# AT32F437xx_v2 register map
Vendor: Keil; Series: AT32F437; File version: 1.0
CPU: CM4 r0p1, little endian, no MPU, FPU, 4 interrupt priority bits
Registers are 32-bit, read-write, reset 0x0 unless marked. A register's access mark holds for its fields unless they carry their own. Offsets are from the block's base; [hi:lo] are bit positions; {n}, {i} and the like mark numbered series.

## USB_OTG1_GLOBAL — USB on-the-go full speed
Base 0x50000000
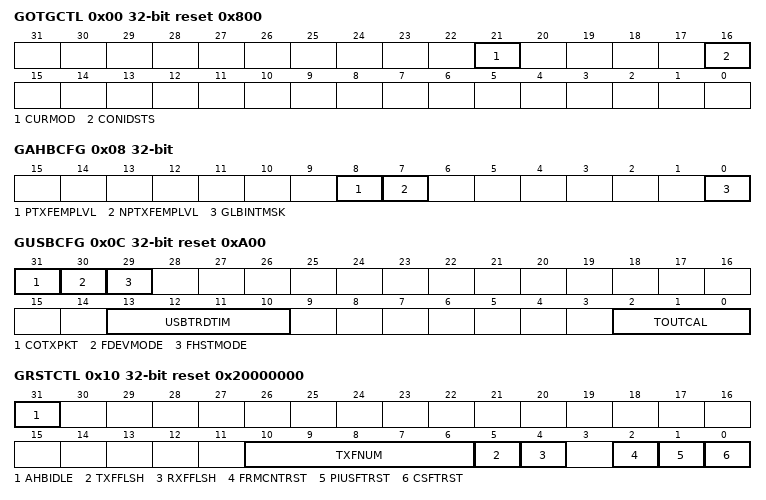
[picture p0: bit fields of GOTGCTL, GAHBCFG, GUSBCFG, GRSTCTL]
0x00 GOTGCTL reset 0x800 — OTGFS control and status register (OTGFS_GOTGCTL)
  [21] CURMOD ro — Current Mode of Operation
  [16] CONIDSTS ro — Connector ID status
0x04 GOTGINT — OTGFS interrupt register (OTGFS_GOTGINT)
  [2] SESENDDET — VBUS is deasserted
0x08 GAHBCFG — OTGFS AHB configuration register (OTGFS_GAHBCFG)
  [8] PTXFEMPLVL — Periodic TxFIFO empty level
  [7] NPTXFEMPLVL — Non-Periodic TxFIFO empty level
  [0] GLBINTMSK — Global interrupt mask
0x0C GUSBCFG reset 0xA00 — USB configuration register (OTGFS_GUSBCFG)
  [31] COTXPKT — Corrupt Tx packet
  [30] FDEVMODE — Force device mode
  [29] FHSTMODE — Force host mode
  [13:10] USBTRDTIM — USB turnaround time
  [2:0] TOUTCAL — FS timeout calibration
0x10 GRSTCTL reset 0x20000000 — OTGFS reset register (OTGFS_GRSTCTL)
  [31] AHBIDLE ro — AHB master idle
  [10:6] TXFNUM — TxFIFO number
  [5] TXFFLSH — TxFIFO flush
  [4] RXFFLSH — RxFIFO flush
  [2] FRMCNTRST — Host frame counter reset
  [1] PIUSFTRST — PIU FS Dedicated Controller Soft Reset
  [0] CSFTRST — Core soft reset
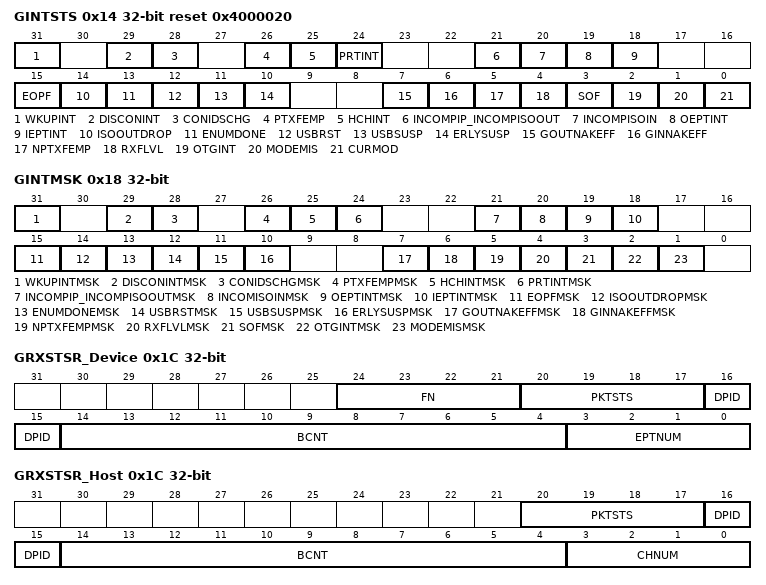
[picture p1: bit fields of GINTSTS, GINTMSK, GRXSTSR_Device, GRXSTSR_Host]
0x14 GINTSTS reset 0x4000020 — OTGFS core interrupt register (OTGFS_GINTSTS)
  [31] WKUPINT — Resume/remote wakeup detected interrupt
  [29] DISCONINT — Disconnect detected interrupt
  [28] CONIDSCHG — Connector ID status change
  [26] PTXFEMP ro — Periodic TxFIFO empty
  [25] HCHINT ro — Host channels interrupt
  [24] PRTINT ro — Host port interrupt
  [21] INCOMPIP_INCOMPISOOUT — Incomplete periodic transfer(Host mode)/Incomplete isochronous OUT transfer(Device mode)
  [20] INCOMPISOIN — Incomplete isochronous IN transfer
  [19] OEPTINT ro — OUT endpoint interrupt
  [18] IEPTINT ro — IN endpoint interrupt
  [15] EOPF — End of periodic frame interrupt
  [14] ISOOUTDROP — Isochronous OUT packet dropped interrupt
  [13] ENUMDONE — Enumeration done
  [12] USBRST — USB reset
  [11] USBSUSP — USB suspend
  [10] ERLYSUSP — Early suspend
  [7] GOUTNAKEFF ro — Global OUT NAK effective
  [6] GINNAKEFF ro — Global IN non-periodic NAK effective
  [5] NPTXFEMP ro — Non-periodic TxFIFO empty
  [4] RXFLVL ro — RxFIFO non-empty
  [3] SOF — Start of frame
  [2] OTGINT ro — OTG interrupt
  [1] MODEMIS — Mode mismatch interrupt
  [0] CURMOD ro — Current mode of operation
0x18 GINTMSK — OTG_FS interrupt mask register (OTG_FS_GINTMSK)
  [31] WKUPINTMSK — Resume/remote wakeup detected interrupt mask
  [29] DISCONINTMSK — Disconnect detected interrupt mask
  [28] CONIDSCHGMSK — Connector ID status change mask
  [26] PTXFEMPMSK — Periodic TxFIFO empty mask
  [25] HCHINTMSK — Host channels interrupt mask
  [24] PRTINTMSK — Host port interrupt mask
  [21] INCOMPIP_INCOMPISOOUTMSK — Incomplete periodic transfer mask(Host mode)/Incomplete isochronous OUT transfer mask(Device mode)
  [20] INCOMISOINMSK — Incomplete isochronous IN transfer mask
  [19] OEPTINTMSK — OUT endpoints interrupt mask
  [18] IEPTINTMSK — IN endpoints interrupt mask
  [15] EOPFMSK — End of periodic frame interrupt mask
  [14] ISOOUTDROPMSK — Isochronous OUT packet dropped interrupt mask
  [13] ENUMDONEMSK — Enumeration done mask
  [12] USBRSTMSK — USB reset mask
  [11] USBSUSPMSK — USB suspend mask
  [10] ERLYSUSPMSK — Early suspend mask
  [7] GOUTNAKEFFMSK — Global OUT NAK effective mask
  [6] GINNAKEFFMSK — Global non-periodic IN NAK effective mask
  [5] NPTXFEMPMSK — Non-periodic TxFIFO empty mask
  [4] RXFLVLMSK — Receive FIFO non-empty mask
  [3] SOFMSK — Start of frame mask
  [2] OTGINTMSK — OTG interrupt mask
  [1] MODEMISMSK — Mode mismatch interrupt mask
0x1C GRXSTSR_Device ro — OTGFS Receive status debug read(Device mode)
  [24:21] FN — Frame number
  [20:17] PKTSTS — Packet status
  [16:15] DPID — Data PID
  [14:4] BCNT — Byte count
  [3:0] EPTNUM — Endpoint number
0x1C GRXSTSR_Host ro (alternate view of GRXSTSR_Device) — OTGFS Receive status debug read(Host mode)
  [20:17] PKTSTS — Packet status
  [16:15] DPID — Data PID
  [14:4] BCNT — Byte count
  [3:0] CHNUM — Channel number
0x24 GRXFSIZ reset 0x200 — OTGFS Receive FIFO size register (OTGFS_GRXFSIZ)
  [15:0] RXFDEP — RxFIFO depth
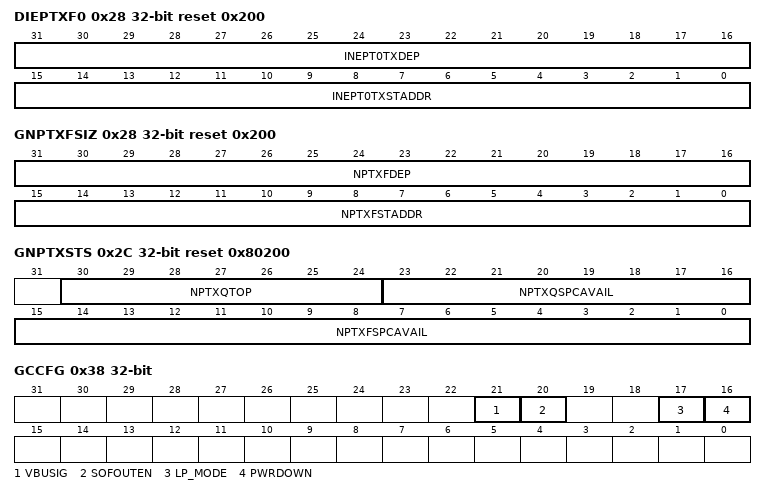
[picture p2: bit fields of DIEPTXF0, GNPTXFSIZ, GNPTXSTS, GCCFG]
0x28 DIEPTXF0 reset 0x200 — IN Endpoint TxFIFO 0 transmit FIFO size register (Device mode)
  [31:16] INEPT0TXDEP — Endpoint 0 TxFIFO depth
  [15:0] INEPT0TXSTADDR — Endpoint 0 transmit RAM start address
0x28 GNPTXFSIZ reset 0x200 (alternate view of DIEPTXF0) — OTGFS non-periodic transmit FIFO size register (Host mode)
  [31:16] NPTXFDEP — Non-periodic TxFIFO depth
  [15:0] NPTXFSTADDR — Non-periodic Transmit RAM Start address
0x2C GNPTXSTS ro reset 0x80200 — OTGFS non-periodic transmit FIFO/queue status register (OTGFS_GNPTXSTS)
  [30:24] NPTXQTOP — Top of the non-periodic transmit request queue
  [23:16] NPTXQSPCAVAIL — Non-periodic transmit request queue space available
  [15:0] NPTXFSPCAVAIL — Non-periodic TxFIFO space available
0x38 GCCFG — OTGFS general core configuration register (OTGFS_GCCFG)
  [21] VBUSIG — VBUS Ignored
  [20] SOFOUTEN — SOF output enable
  [17] LP_MODE — Low power mode
  [16] PWRDOWN — Power down
0x3C GUID reset 0x1000 — Product ID register
  [31:0] USERID — Product ID field
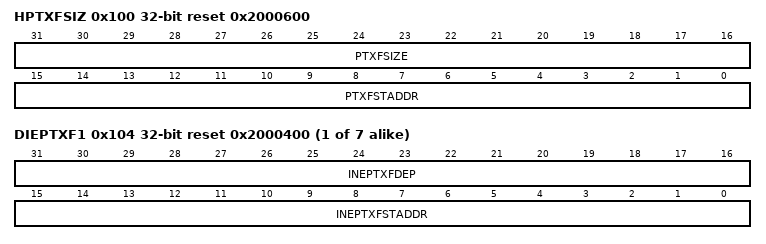
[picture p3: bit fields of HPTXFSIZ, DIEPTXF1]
0x100 HPTXFSIZ reset 0x2000600 — OTGFS Host periodic transmit FIFO size register (OTGFS_HPTXFSIZ)
  [31:16] PTXFSIZE — Host periodic TxFIFO depth
  [15:0] PTXFSTADDR — Host periodic TxFIFO start address
{0x100+4i} DIEPTXF{i} reset 0x2000400 (i=1..7) — OTGFS device IN endpoint transmit FIFO size register (OTGFS_DIEPTXF{i})
  [31:16] INEPTXFDEP — IN endpoint TxFIFO depth
  [15:0] INEPTXFSTADDR — IN endpoint FIFO{i} transmit RAM start address

## USB_OTG2_GLOBAL — USB on the go full speed
Base 0x40040000
Registers as USB_OTG1_GLOBAL; these are added or differ:
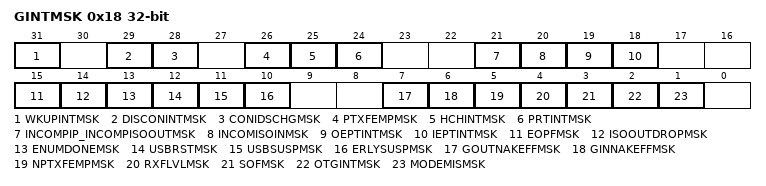
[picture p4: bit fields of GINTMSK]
0x18 GINTMSK — OTG_FS interrupt mask register (OTG_FS_GINTMSK)
  [31] WKUPINTMSK — Resume/remote wakeup detected interrupt mask
  [29] DISCONINTMSK — Disconnect detected interrupt mask
  [28] CONIDSCHGMSK — Connector ID status change mask
  [26] PTXFEMPMSK — Periodic TxFIFO empty mask
  [25] HCHINTMSK — Host channels interrupt mask
  [24] PRTINTMSK ro — Host port interrupt mask
  [21] INCOMPIP_INCOMPISOOUTMSK — Incomplete periodic transfer mask(Host mode)/Incomplete isochronous OUT transfer mask(Device mode)
  [20] INCOMISOINMSK — Incomplete isochronous IN transfer mask
  [19] OEPTINTMSK — OUT endpoints interrupt mask
  [18] IEPTINTMSK — IN endpoints interrupt mask
  [15] EOPFMSK — End of periodic frame interrupt mask
  [14] ISOOUTDROPMSK — Isochronous OUT packet dropped interrupt mask
  [13] ENUMDONEMSK — Enumeration done mask
  [12] USBRSTMSK — USB reset mask
  [11] USBSUSPMSK — USB suspend mask
  [10] ERLYSUSPMSK — Early suspend mask
  [7] GOUTNAKEFFMSK — Global OUT NAK effective mask
  [6] GINNAKEFFMSK — Global non-periodic IN NAK effective mask
  [5] NPTXFEMPMSK — Non-periodic TxFIFO empty mask
  [4] RXFLVLMSK — Receive FIFO non-empty mask
  [3] SOFMSK — Start of frame mask
  [2] OTGINTMSK — OTG interrupt mask
  [1] MODEMISMSK — Mode mismatch interrupt mask
